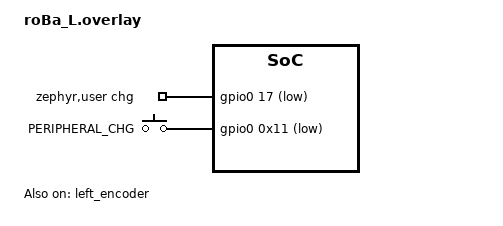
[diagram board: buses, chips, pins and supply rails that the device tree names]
#include "roBa.dtsi"

#include <dt-bindings/gpio/gpio.h>
#include <dt-bindings/input/input-event-codes.h>

&kscan0 {
        col-gpios
            = <&xiao_d 10 GPIO_ACTIVE_HIGH>
            , <&xiao_d 9 GPIO_ACTIVE_HIGH> 
            , <&xiao_d 8 GPIO_ACTIVE_HIGH> 
            , <&xiao_d 7 GPIO_ACTIVE_HIGH> 
            , <&gpio0 10 GPIO_ACTIVE_HIGH>
            , <&gpio0 9 GPIO_ACTIVE_HIGH>
            ;
};

&left_encoder {
    status = "okay";
};


/ {
  zephyr,user {
    chg-gpios
      = <&gpio0 17 (GPIO_ACTIVE_LOW | GPIO_PULL_UP)>;
  };
};
 
/ {
  chg_keys: chg_keys {
    compatible = "gpio-keys";
    status = "okay";

    peri_chg0: peri_chg0 {
      label = "PERIPHERAL_CHG";

      gpios = <&gpio0 0x11 (GPIO_PULL_UP | GPIO_ACTIVE_LOW)>;
      zephyr,code = <INPUT_KEY_F24>;
    };
  };
};


&chg_input_split {
  device = <&chg_keys>;
};



